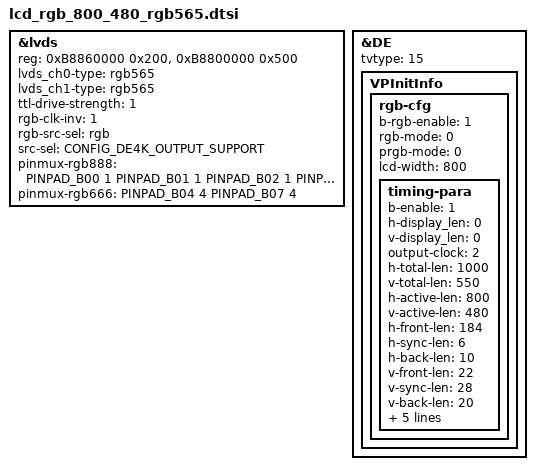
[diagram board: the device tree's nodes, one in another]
&lvds {
	reg = <0xB8860000 0x200>, <0xB8800000 0x500>;
	/*
	 * "lvds"		: LVDS screen
	 * "rgb888" 	: RGB screen
	 * "rgb666" 	: RGB screen
	 * "rgb565" 	: RGB screen
	 * "i2so"		: I2S OUT
	 * "gpio"		: only GPIO out
	 */
	lvds_ch0-type = "rgb565";
	lvds_ch1-type = "rgb565";

	/*
	 * 0: LVDS_TTL_DRIVE_STRENGTH_WEAKEST,
	 * 1: LVDS_TTL_DRIVE_STRENGTH_NORMAL,
	 * 2: LVDS_TTL_DRIVE_STRENGTH_ENHANCE,
	 * 3: LVDS_TTL_DRIVE_STRENGTH_STRONGEST,
	 */
	ttl-drive-strength = <1>;

	/*
	 *0 : RGB CLOCK NO INVERSION
	 *1 : RGB CLOCK INVERSION
	 */
	rgb-clk-inv = <1>;

	/*
	 * rgb gbr bgr
	 * rbg grb brg
	 */
	rgb-src-sel = "rgb";

	/*
	 * 0: E_SRC_SEL_FXDE = 0
	 * 1: E_SRC_SEL_4KDE = 1
	 * 2: E_SRC_SEL_HDMI_RX = 2
	 * 3: E_SRC_SEL_FXDE_ = 3
	 * 4: E_SRC_2_SEL_FXDE_LOW_TO_HIGH = 4 //need clsoe pq
	 * 5: E_SRC_2_SEL_DE4K_LOW_TO_HIGH = 5 //need clsoe pq
	 * 6: E_SRC_2_SEL_HDMI_RX_LOW_TO_HIGH = 6 //need clsoe pq
	 * 7: E_SRC_2_SEL_PQ_LOW_TO_HIGH = 7
	 */
	src-sel = <CONFIG_DE4K_OUTPUT_SUPPORT>;

	pinmux-rgb888 = <PINPAD_B00 1 PINPAD_B01 1 PINPAD_B02 1 PINPAD_B03 1 PINPAD_B04 1 PINPAD_B05 1 PINPAD_B06 1 PINPAD_B07 1>;/*RGB888 other pin set*/
	pinmux-rgb666 = <PINPAD_B04 4 PINPAD_B07 4>; /*RGB666 other pin set*/
	// status = "okay";
};

&DE {
	tvtype = <15>;
	VPInitInfo {
		rgb-cfg{
			b-rgb-enable = <1>;
			/*
			 * 0: MODE_PRGB
			 * 1: MODE_SRGB
			 */
			rgb-mode = <0>;
			/*
			 * 0: MODE_PRGB_888_10bit
			 * 1: MODE_PRGB_666
			 */
			prgb-mode = <0>;
			lcd-width = <800>;
			timing-para {
				/* bool type, 0 or 1*/
				b-enable = <1>;

				h-display_len = <0>;
				v-display_len = <0>;

				/*
				 * VPO_RGB_CLOCK_27M = 1,
				 * VPO_RGB_CLOCK_33M = 2,
				 * VPO_RGB_CLOCK_49M = 3,
				 * VPO_RGB_CLOCK_66M = 4,
				 * VPO_RGB_CLOCK_74M = 5,
				 * VPO_RGB_CLOCK_85M = 6,
				 * VPO_RGB_CLOCK_108M = 7,
				 * VPO_RGB_CLOCK_6_6M = 8,
				 * VPO_RGB_CLOCK_9M = 9,
				 * VPO_RGB_CLOCK_39_6M = 10,
				 * VPO_RGB_CLOCK_74_25M = 11,
				 * VPO_RGB_CLOCK_148_5M = 12,
				 * VPO_RGB_CLOCK_54M = 13,
				 * VPO_RGB_CLOCK_132M = 14,//H1600
				 * VPO_RGB_CLOCK_297M = 15,//H1600 only De4k
				 * VPO_RGB_CLOCK_DPLL = 0xFF,//H1600
				*/
				output-clock = <2>;

				h-total-len = <1000>;
				v-total-len = <550>;

				h-active-len = <800>;
				v-active-len = <480>;

				h-front-len = <184>;
				h-sync-len = <6>;
				h-back-len = <10>;

				v-front-len = <22>;
				v-sync-len = <28>;
				v-back-len = <20>;

				/* bool type, 0 or 1*/
				h-sync-level = <0>;
				/* bool type, 0 or 1*/
				v-sync-level = <0>;

				/* bool type, 0 or 1*/
				active-polarity = <1>;
				frame-rate = <60000>;

				/*
				31	De_dig_pll_en
				25:16	DE_DIG_PLL_M_ctrl
				13:8	DE_DIG_PLL_N_ctrl
				5:0	DE_DIG_PLL_L_ctrl
				de_digpll_clock = 24 *(M+1)/((N+1)*(L+1))
				*/
				dpll-clock-reg-value = <0x0>;
			};
		};
	};
};
